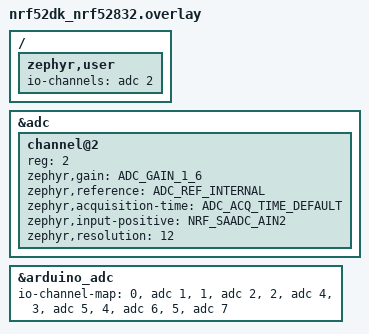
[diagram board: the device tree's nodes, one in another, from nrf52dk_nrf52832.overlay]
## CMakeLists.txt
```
cmake_minimum_required(VERSION 3.20.0)
find_package(Zephyr REQUIRED HINTS $ENV{ZEPHYR_BASE})

project(SensorTest)

target_sources(app PRIVATE src/main.c)
```

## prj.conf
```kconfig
# enable GPIO
CONFIG_GPIO=y

# enable ADC
CONFIG_ADC=y
```

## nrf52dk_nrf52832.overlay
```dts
/ {
    zephyr,user {
        io-channels = <&adc 2>;
    };
};
&adc {
    status = "okay";  // Ensure the ADC device is enabled
    #address-cells = <1>;
    #size-cells = <0>;

    channel@2 {
        reg = <2>;
        zephyr,gain = "ADC_GAIN_1_6";
        zephyr,reference = "ADC_REF_INTERNAL";
        zephyr,acquisition-time = <ADC_ACQ_TIME_DEFAULT>;
        zephyr,input-positive = <NRF_SAADC_AIN2>;  // Updated for P0.04
        zephyr,resolution = <12>;
    };
};
&arduino_adc {
	io-channel-map = <0 &adc 1>, <1 &adc 2>, <2 &adc 4>, <3 &adc 5>, <4 &adc 6>, <5 &adc 7>;
};
```

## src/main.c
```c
/*
 * Copyright (c) 2016 Intel Corporation
 *
 * SPDX-License-Identifier: Apache-2.0
 */

	


/* 1000 msec = 1 sec */
#define SLEEP_TIME_MS 1000

/* The devicetree node identifier for the "led0" alias. */
#define LED1_NODE DT_NODELABEL(led1)

/*
 * A build error on this line means your board is unsupported.
 * See the sample documentation for information on how to fix this.
 */
static const struct gpio_dt_spec led = GPIO_DT_SPEC_GET(LED1_NODE, gpios);

#if !DT_NODE_EXISTS(DT_PATH(zephyr_user)) || \
	!DT_NODE_HAS_PROP(DT_PATH(zephyr_user), io_channels)
#error "No suitable devicetree overlay specified"
#endif

#define DT_SPEC_AND_COMMA(node_id, prop, idx) \
	ADC_DT_SPEC_GET_BY_IDX(node_id, idx),

/* Data of ADC io-channels specified in devicetree. */
static const struct adc_dt_spec adc_channels[] = {
	DT_FOREACH_PROP_ELEM(DT_PATH(zephyr_user), io_channels,
			     DT_SPEC_AND_COMMA)
};


int main(void)
{
	int ret;
	int count = 0;
	bool led_state = true;

	int err;
	uint16_t buf;
	struct adc_sequence sequence = {
		.buffer = &buf,
	/* buffer size in bytes, not number of samples */
		.buffer_size = sizeof(buf),
	};

	/* Configure channels individually prior to sampling. */
	for (size_t i = 0U; i < ARRAY_SIZE(adc_channels); i++) {
		if (!adc_is_ready_dt(&adc_channels[i])) {
			printk("ADC controller device %s not ready\n", adc_channels[i].dev->name);
			return 0;
		}

		err = adc_channel_setup_dt(&adc_channels[i]);
		if (err < 0) {
			printk("Could not setup channel #%d (%d)\n", i, err);
			return 0;
		}
	}

	if (!gpio_is_ready_dt(&led)) {
		return 0;
	}

	ret = gpio_pin_configure_dt(&led, GPIO_OUTPUT_ACTIVE);
	if (ret < 0) {
		return 0;
	}
	
#ifndef CONFIG_COVERAGE
	while (1) {
#else
	for (int k = 0; k < 10; k++) {
#endif
		printk("ADC reading[%u]:\n", count++);
		for (size_t i = 0U; i < ARRAY_SIZE(adc_channels); i++) {
			int32_t val_mv;

			printk("- %s, channel %d: ",
			       adc_channels[i].dev->name,
			       adc_channels[i].channel_id);

			(void)adc_sequence_init_dt(&adc_channels[i], &sequence);

			err = adc_read_dt(&adc_channels[i], &sequence);
			if (err < 0) {
				printk("Could not read (%d)\n", err);
				continue;
			}

			/*
			 * If using differential mode, the 16 bit value
			 * in the ADC sample buffer should be a signed 2's
			 * complement value.
			 */
			if (adc_channels[i].channel_cfg.differential) {
				val_mv = (int32_t)((int16_t)buf);
			} else {
				val_mv = (int32_t)buf;
			}
			printk("%"PRId32, val_mv);
			err = adc_raw_to_millivolts_dt(&adc_channels[i],
						       &val_mv);
			/* conversion to mV may not be supported, skip if not */
			if (err < 0) {
				printk(" (value in mV not available)\n");
			} else {
				printk(" = %"PRId32" mV\n", val_mv);
			}
		}


		ret = gpio_pin_toggle_dt(&led);
		if (ret < 0)
		{
			return 0;
		}

		led_state = !led_state;
		printf("LED state: %s\n", led_state ? "ON" : "OFF");
		k_sleep(K_MSEC(1000));
	}
	return 0;
}
```
